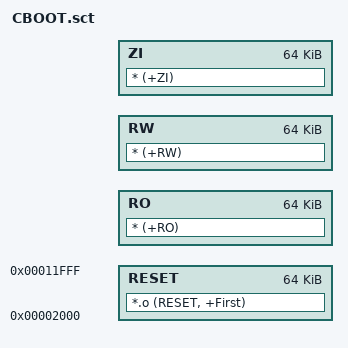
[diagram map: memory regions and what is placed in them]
;******************************************************************************
;
; bl_link.sct - Scatter file for RV-MDK.
;
; Copyright (c) 2006-2014 Texas Instruments Incorporated.  All rights reserved.
; Software License Agreement
; 
; Texas Instruments (TI) is supplying this software for use solely and
; exclusively on TI's microcontroller products. The software is owned by
; TI and/or its suppliers, and is protected under applicable copyright
; laws. You may not combine this software with "viral" open-source
; software in order to form a larger program.
; 
; THIS SOFTWARE IS PROVIDED "AS IS" AND WITH ALL FAULTS.
; NO WARRANTIES, WHETHER EXPRESS, IMPLIED OR STATUTORY, INCLUDING, BUT
; NOT LIMITED TO, IMPLIED WARRANTIES OF MERCHANTABILITY AND FITNESS FOR
; A PARTICULAR PURPOSE APPLY TO THIS SOFTWARE. TI SHALL NOT, UNDER ANY
; CIRCUMSTANCES, BE LIABLE FOR SPECIAL, INCIDENTAL, OR CONSEQUENTIAL
; DAMAGES, FOR ANY REASON WHATSOEVER.
; 
; This is part of revision 2.1.0.12573 of the Tiva Firmware Development Package.
;
;******************************************************************************

;
; The contents of this application reside in flash.
;
FLASH 0x00002000 0x00010000
{
    ;
    ; Place the vector table and reset handlers into flash.
    ;
    RESET 0x00002000 0x00010000
    {
        *.o (RESET, +First)
    }

    ;
    ; Place the remainder of the code and read-only data into sram.
    ;
    RO +0x20000000-0x4000 0x00010000
    {
        * (+RO)
    }

    ;
    ; Follow the code with the read/write data.
    ;
    RW +0 0x00010000
    {
        * (+RW)
    }

    ;
    ; Follow the read/write data with the zero-init data.
    ;
    ZI +0 0x00010000
    {
        * (+ZI)
    }
}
